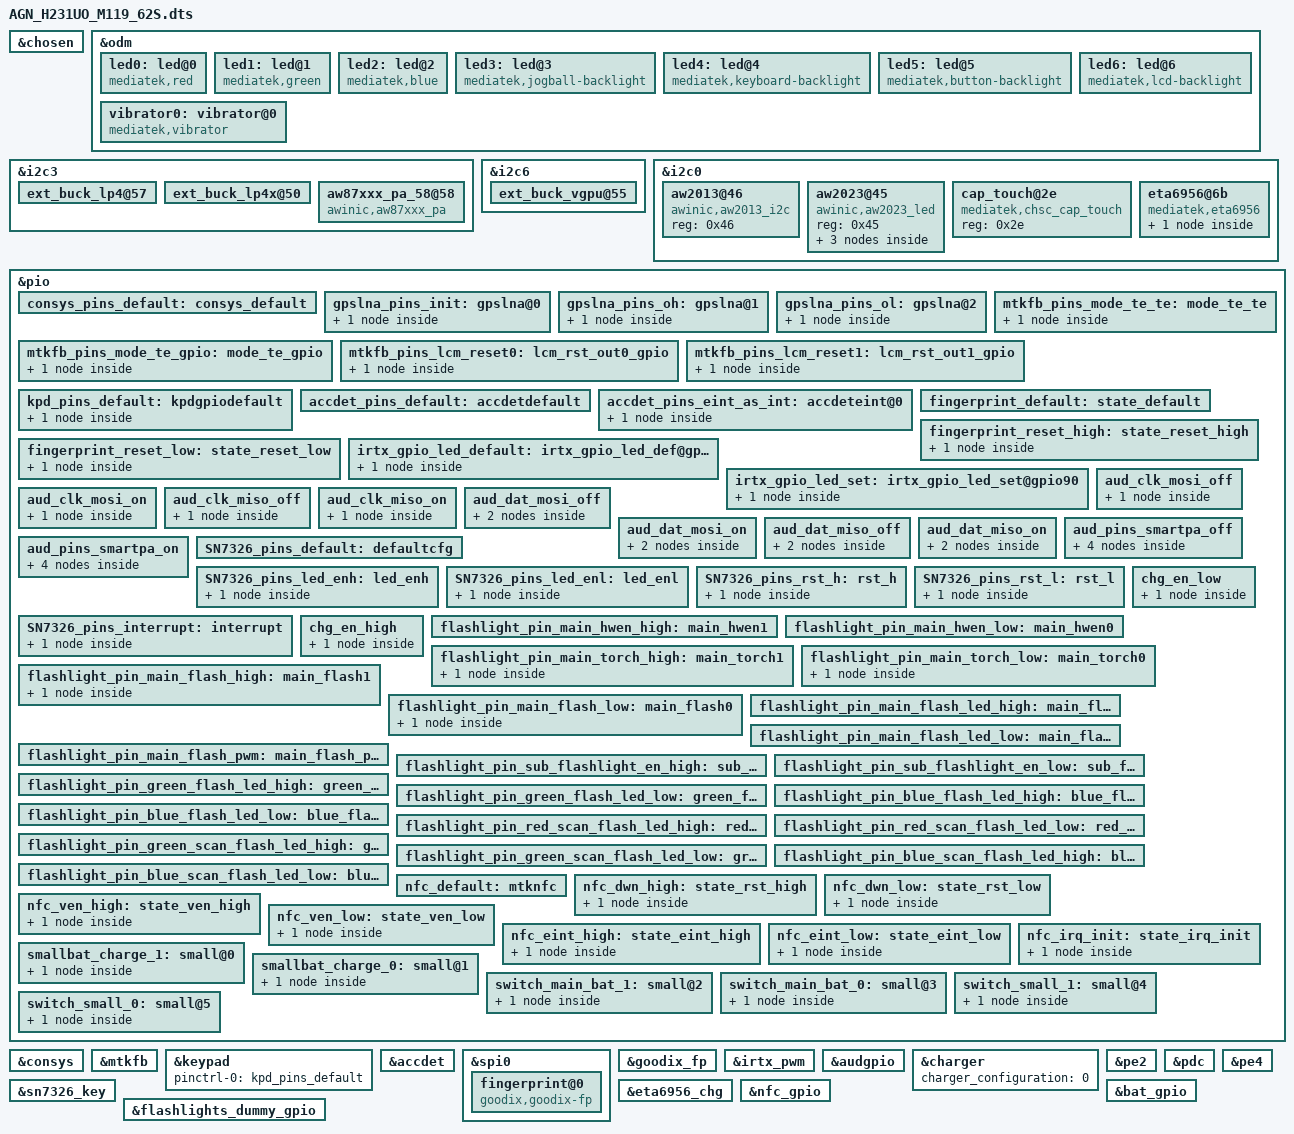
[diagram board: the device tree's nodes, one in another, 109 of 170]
// SPDX-License-Identifier: GPL-2.0+
/*
 * Copyright (c) 2019 MediaTek Inc.
 *
 */

#include <dt-bindings/interrupt-controller/arm-gic.h>
#include <dt-bindings/interrupt-controller/irq.h>
#include <dt-bindings/pinctrl/mt6765-pinfunc.h>
#include <dt-bindings/clock/mt6765-clk.h>

/dts-v1/;
/plugin/;

/* chosen */
&chosen {

	/* fpga may has no lk, we need to specify display info here */
	/* fb buffer is reserved using this dts by memory node above */
	atag,videolfb-fb_base_h = <0x0>;
	atag,videolfb-fb_base_l = <0x5e605000>;
	atag,videolfb-islcmfound = <1>;
	/* because no lk, so lcm is not inited */
	atag,videolfb-islcm_inited = <0>;
	atag,videolfb-fps= <6000>;
	atag,videolfb-vramSize= <0x017bb000>;
	atag,videolfb-lcmname= "nt35695B_fhd_dsi_cmd_auo_rt5081_drv";
};

&odm {
	led0:led@0 {
		compatible = "mediatek,red";
		led_mode = <0>;
		data = <2>;
		pwm_config = <0 0 0 0 0>;
	};
	led1:led@1 {
		compatible = "mediatek,green";
		led_mode = <0>;
		data = <1>;
		pwm_config = <0 0 0 0 0>;
	};
	led2:led@2 {
		compatible = "mediatek,blue";
		led_mode = <0>;
		data = <1>;
		pwm_config = <0 0 0 0 0>;
	};
	led3:led@3 {
		compatible = "mediatek,jogball-backlight";
		led_mode = <0>;
		data = <1>;
		pwm_config = <0 0 0 0 0>;
	};
	led4:led@4 {
		compatible = "mediatek,keyboard-backlight";
		led_mode = <0>;
		data = <1>;
		pwm_config = <0 0 0 0 0>;
	};
	led5:led@5 {
		compatible = "mediatek,button-backlight";
		led_mode = <2>;
		data = <1>;
		gpio = <&pio 165 0x0>;
		pwm_config = <0 0 0 0 0>;
	};
	led6:led@6 {
		compatible = "mediatek,lcd-backlight";
		led_mode = <5>;
		data = <1>;
		pwm_config = <0 3 0 0 0>;
	};
	vibrator0:vibrator@0 {
		compatible = "mediatek,vibrator";
		vib_timer = <25>;
		vib_limit = <9>;
		vib_vol= <9>;
	};
};

&i2c3 {
	ext_buck_lp4@57 {
		regulator-name ="ext_buck_vdd2";
		regulator-min-microvolt = <300000>;
		regulator-max-microvolt = <1300000>;
		vsel_pin = <0>;
	};

	ext_buck_lp4x@50 {
		regulator-name ="ext_buck_vddq";
		regulator-min-microvolt = <300000>;
		regulator-max-microvolt = <1300000>;
		vsel_pin = <1>;
	};
};

&i2c6 {
	ext_buck_vgpu@55 {
		regulator-name ="ext_buck_vgpu";
		regulator-min-microvolt = <300000>;
		regulator-max-microvolt = <1300000>;
		vsel_pin = <2>;
	};
};

&i2c0 {
	aw2013@46 {
		compatible = "awinic,aw2013_i2c";
		reg = <0x46>;
		status = "okay";
	};

	aw2023@45 {
	compatible = "awinic,aw2023_led";
	reg = <0x45>;
	status = "okay";
	
	aw2023,green  {
		aw2023,name = "green";
		aw2023,id = <0>;
		aw2023,imax = <1>;
		aw2023,led-current = <15>;
		aw2023,max-brightness = <255>;
		aw2023,rise-time-ms = <6>;
		aw2023,hold-time-ms = <0>;
		aw2023,fall-time-ms = <6>;
		aw2023,off-time-ms = <4>;
	};

	aw2023,scan_led {
		aw2023,name = "scan_led";
		aw2023,id = <1>;
		aw2023,imax = <1>;
		aw2023,led-current = <15>;
		aw2023,max-brightness = <255>;
		aw2023,rise-time-ms = <6>;
		aw2023,hold-time-ms = <0>;
		aw2023,fall-time-ms = <6>;
		aw2023,off-time-ms = <4>;
	};

	aw2023,blue {
		aw2023,name = "blue";
		aw2023,id = <2>;
		aw2023,imax = <1>;
		aw2023,led-current = <15>;
		aw2023,max-brightness = <255>;
		aw2023,rise-time-ms = <6>;
		aw2023,hold-time-ms = <0>;
		aw2023,fall-time-ms = <6>;
		aw2023,off-time-ms = <4>;
	};
	};
	};


&i2c3 {
/* AWINIC AW87XXX Smart K PA */
	aw87xxx_pa_58@58 {
		compatible = "awinic,aw87xxx_pa";
		reg = <0x58>;
		reset-gpio = <&pio 159 0>;
		pa-channel = < 0 >;
		status = "okay";
	};
/* AWINIC AW87XXX Smart K PA End */
};

/* CONSYS GPIO standardization */
&pio {
	consys_pins_default: consys_default {
	};
	gpslna_pins_init: gpslna@0 {
		pins_cmd_dat {
			pinmux = <PINMUX_GPIO153__FUNC_GPIO153>;
			slew-rate = <0>;
			bias-disable;
			output-low;
		};
	};
	gpslna_pins_oh: gpslna@1 {
		pins_cmd_dat {
			pinmux = <PINMUX_GPIO153__FUNC_GPIO153>;
			slew-rate = <1>;
			output-high;
		};
	};
	gpslna_pins_ol: gpslna@2 {
		pins_cmd_dat {
			pinmux = <PINMUX_GPIO153__FUNC_GPIO153>;
			slew-rate = <1>;
			output-low;
		};
	};
};
&consys {
	pinctrl-names = "default", "gps_lna_state_init",
		"gps_lna_state_oh", "gps_lna_state_ol";
	pinctrl-0 = <&consys_pins_default>;
	pinctrl-1 = <&gpslna_pins_init>;
	pinctrl-2 = <&gpslna_pins_oh>;
	pinctrl-3 = <&gpslna_pins_ol>;
	config_vcn28_pin = <1>;
	status = "okay";
};
/* CONSYS end */
/* DISPSYS GPIO standardization */
&pio {
	mtkfb_pins_mode_te_gpio: mode_te_gpio {
		pins_cmd_dat {
			pinmux = <PINMUX_GPIO44__FUNC_DSI_TE>;
		};
	};

	mtkfb_pins_mode_te_te: mode_te_te {
		pins_cmd_dat {
			pinmux = <PINMUX_GPIO44__FUNC_DSI_TE>;
		};
	};

	mtkfb_pins_lcm_reset0: lcm_rst_out0_gpio {
		pins_cmd_dat {
			pinmux = <PINMUX_GPIO45__FUNC_GPIO45>;
			slew-rate = <1>;
			output-low;
		};
	};

	mtkfb_pins_lcm_reset1: lcm_rst_out1_gpio {
		pins_cmd_dat {
			pinmux = <PINMUX_GPIO45__FUNC_GPIO45>;
			slew-rate = <1>;
			output-high;
		};
	};


};

&mtkfb {
	pinctrl-names = "mode_te_gpio", "mode_te_te", "lcm_rst_out0_gpio",
		"lcm_rst_out1_gpio";
	pinctrl-0 = <&mtkfb_pins_mode_te_gpio>;
	pinctrl-1 = <&mtkfb_pins_mode_te_te>;
	pinctrl-2 = <&mtkfb_pins_lcm_reset0>;
	pinctrl-3 = <&mtkfb_pins_lcm_reset1>;
	status = "okay";
};
/* DISPSYS GPIO standardization end */

&keypad {
	pinctrl-names = "default";
	pinctrl-0 = <&kpd_pins_default>;
};

&pio {
	kpd_pins_default: kpdgpiodefault {
		pins_cmd_dat {
			pinmux = <PINMUX_GPIO93__FUNC_KPCOL0>;
			bias-pull-up = <MTK_PUPD_SET_R1R0_10>;
			output-low;
			input-schmitt-enable;
		};
	};
};


/* accdet start */
&accdet {
	accdet-mic-vol = <6>;
	headset-mode-setting = <0x500 0x500 1 0x1f0 0x800 0x800 0x20 0x44>;
	accdet-plugout-debounce = <1>;
	accdet-mic-mode = <1>;
	headset-eint-level-pol = <8>;
	headset-three-key-threshold = <0 80 220 400>;
	headset-three-key-threshold-CDD = <0 121 192 600>;
	headset-four-key-threshold = <0 58 121 192 400>;
	pinctrl-names = "default", "state_eint_as_int";
	pinctrl-0 = <&accdet_pins_default>;
	pinctrl-1 = <&accdet_pins_eint_as_int>;
	status = "okay";
};
&pio {
	accdet_pins_default: accdetdefault {
	};
	accdet_pins_eint_as_int: accdeteint@0 {
		pins_cmd_dat {
			pinmux = <PINMUX_GPIO9__FUNC_GPIO9>;
			slew-rate = <0>;
			bias-disable;
		};
	};
};
/* accdet end */


&i2c0 {
	#address-cells = <1>;
	#size-cells = <0>;
	clock-frequency = <400000>;
	mediatek,use-open-drain;
	cap_touch@2e {
		compatible = "mediatek,chsc_cap_touch";
		reg = <0x2e>;
		status = "okay";
	};
};


/* FINGERPRINT start */
&spi0 {
	#address-cells = <1>;
	#size-cells = <0>;
	fingerprint@0 {
		compatible = "goodix,goodix-fp";
		reg = <0>;
		spi-max-frequency = <8000000>;
		netlink-event = <30>;
		status = "okay";
	};
};

&goodix_fp {
	pinctrl-names = "default", "reset_high", "reset_low";
	pinctrl-0 = <&fingerprint_default>;
	pinctrl-1 = <&fingerprint_reset_high>;
	pinctrl-2 = <&fingerprint_reset_low>;
	status = "okay";
};

&pio {
	fingerprint_default: state_default {
	};
	fingerprint_reset_high: state_reset_high {
		pins_cmd_dat {
			pinmux = <PINMUX_GPIO172__FUNC_GPIO172>;
			slew-rate = <1>;
			output-high;
		};
	};
	fingerprint_reset_low: state_reset_low {
		pins_cmd_dat {
			pinmux = <PINMUX_GPIO172__FUNC_GPIO172>;
			slew-rate = <1>;
			output-low;
		};
	};
};
/* FINGERPRINT end */

/* IRTX GPIO end */
&irtx_pwm {
	pinctrl-names = "irtx_gpio_led_default", "irtx_gpio_led_set";
	pinctrl-0 = <&irtx_gpio_led_default>;
	pinctrl-1 = <&irtx_gpio_led_set>;
	status = "okay";
};
&pio {
	irtx_gpio_led_default:irtx_gpio_led_def@gpio90 {
		pins_cmd_dat {
			pinmux = <PINMUX_GPIO90__FUNC_GPIO90>;
			slew-rate = <1>;
			bias-disable;
			output-low;
			input-schmitt-enable = <0>;
		};
	};

	irtx_gpio_led_set:irtx_gpio_led_set@gpio90 {
		pins_cmd_dat {
			pinmux = <PINMUX_GPIO90__FUNC_PWM0>;
			slew-rate = <1>;
			output-high;
		};
	};
};
/* IRTX GPIO Settings -End */

/* AUDIO GPIO standardization */
&audgpio {
	pinctrl-names = "aud_clk_mosi_off",
			"aud_clk_mosi_on",
			"aud_clk_miso_off",
			"aud_clk_miso_on",
			"aud_dat_mosi_off",
			"aud_dat_mosi_on",
			"aud_dat_miso_off",
			"aud_dat_miso_on",
			"aud_smartpa_off",
			"aud_smartpa_on";
	pinctrl-0 = <&aud_clk_mosi_off>;
	pinctrl-1 = <&aud_clk_mosi_on>;
	pinctrl-2 = <&aud_clk_miso_off>;
	pinctrl-3 = <&aud_clk_miso_on>;
	pinctrl-4 = <&aud_dat_mosi_off>;
	pinctrl-5 = <&aud_dat_mosi_on>;
	pinctrl-6 = <&aud_dat_miso_off>;
	pinctrl-7 = <&aud_dat_miso_on>;
	pinctrl-8 = <&aud_pins_smartpa_off>;
	pinctrl-9 = <&aud_pins_smartpa_on>;
	status = "okay";
};

&pio {
	aud_clk_mosi_off: aud_clk_mosi_off {
		pins_cmd0_dat {
			pinmux = <PINMUX_GPIO136__FUNC_GPIO136>;
		};
	};

	aud_clk_mosi_on: aud_clk_mosi_on {
		pins_cmd0_dat {
			pinmux = <PINMUX_GPIO136__FUNC_AUD_CLK_MOSI>;
		};
	};

	aud_clk_miso_off: aud_clk_miso_off {
		pins_cmd0_dat {
			pinmux = <PINMUX_GPIO140__FUNC_GPIO140>;
		};
	};

	aud_clk_miso_on: aud_clk_miso_on {
		pins_cmd0_dat {
			pinmux = <PINMUX_GPIO140__FUNC_AUD_CLK_MISO>;
		};
	};

	aud_dat_mosi_off: aud_dat_mosi_off {
		pins_cmd1_dat {
			pinmux = <PINMUX_GPIO138__FUNC_GPIO138>;
			input-enable;
			slew-rate = <0>;
			bias-disable;
		};
		pins_cmd2_dat {
			pinmux = <PINMUX_GPIO139__FUNC_GPIO139>;
			input-enable;
			slew-rate = <0>;
			bias-disable;
		};
	};

	aud_dat_mosi_on: aud_dat_mosi_on {
		pins_cmd1_dat {
			pinmux = <PINMUX_GPIO138__FUNC_AUD_DAT_MOSI0>;
		};
		pins_cmd2_dat {
			pinmux = <PINMUX_GPIO139__FUNC_AUD_DAT_MOSI1>;
		};
	};

	aud_dat_miso_off: aud_dat_miso_off {
		pins_cmd1_dat {
			pinmux = <PINMUX_GPIO142__FUNC_GPIO142>;
			input-enable;
			slew-rate = <0>;
			bias-disable;
		};
		pins_cmd2_dat {
			pinmux = <PINMUX_GPIO143__FUNC_GPIO143>;
			input-enable;
			slew-rate = <0>;
			bias-disable;
		};
	};

	aud_dat_miso_on: aud_dat_miso_on {
		pins_cmd1_dat {
			pinmux = <PINMUX_GPIO142__FUNC_AUD_DAT_MISO0>;
		};
		pins_cmd2_dat {
			pinmux = <PINMUX_GPIO143__FUNC_AUD_DAT_MISO1>;
		};
	};

	aud_pins_smartpa_off: aud_pins_smartpa_off {
		pins_cmd0_dat {
			pinmux = <PINMUX_GPIO17__FUNC_GPIO17>;
		};
		pins_cmd1_dat {
			pinmux = <PINMUX_GPIO18__FUNC_GPIO18>;
		};
		pins_cmd2_dat {
			pinmux = <PINMUX_GPIO19__FUNC_GPIO19>;
		};
		pins_cmd3_dat {
			pinmux = <PINMUX_GPIO20__FUNC_GPIO20>;
		};
	};

	aud_pins_smartpa_on: aud_pins_smartpa_on {
		pins_cmd0_dat {
			pinmux = <PINMUX_GPIO17__FUNC_I2S0_DI>;
		};
		pins_cmd1_dat {
			pinmux = <PINMUX_GPIO18__FUNC_I2S3_BCK>;
		};
		pins_cmd2_dat {
			pinmux = <PINMUX_GPIO19__FUNC_I2S3_LRCK>;
		};
		pins_cmd3_dat {
			pinmux = <PINMUX_GPIO20__FUNC_I2S3_DO>;
		};
	};
};
/* AUDIO end */



&i2c3 {

};

&charger {
	charger_configuration= <0>;
};

&pe2 {
	dcs_chg1_charger_current = <2000000>;
	dcs_chg2_charger_current = <2000000>;
};

&pdc {
	pd_vbus_upper_bound = <12000000>;
	dcs_chg1_charger_current = <2000000>;
	dcs_chg2_charger_current = <2000000>;
};

&pe4 {
	dcs_chg1_charger_current = <2000000>;
	dcs_chg2_charger_current = <2000000>;
};
/*SN7326, start */

&pio {
	SN7326_pins_default:defaultcfg {
	};
	SN7326_pins_led_enh:led_enh {
			pins_cmd_dat {
			pinmux = <PINMUX_GPIO165__FUNC_GPIO165>;
			slew-rate = <1>;
			output-high;
		};
	};
	SN7326_pins_led_enl:led_enl {
			pins_cmd_dat {
			pinmux = <PINMUX_GPIO165__FUNC_GPIO165>;
			slew-rate = <1>;
			output-low;
		};
	};
	SN7326_pins_rst_h:rst_h {
			pins_cmd_dat {
			pinmux = <PINMUX_GPIO171__FUNC_GPIO171>;
			slew-rate = <1>;
			output-high;
		};
	};
	SN7326_pins_rst_l:rst_l {
			pins_cmd_dat {
			pinmux = <PINMUX_GPIO171__FUNC_GPIO171>;
			slew-rate = <1>;
			output-low;
		};
	};
	SN7326_pins_interrupt:interrupt {
			pins_cmd_dat {
			pinmux = <PINMUX_GPIO12__FUNC_GPIO12>;
			slew-rate = <0>;
			bias-pull-up = <00>;
		};
	};
};

&sn7326_key {
	pinctrl-names = "default", "led_enh", "led_enl", "rst_h", "rst_l", "interrupt";
	pinctrl-0 = <&SN7326_pins_default>;
	pinctrl-1 = <&SN7326_pins_led_enh>;
	pinctrl-2 = <&SN7326_pins_led_enl>;
	pinctrl-3 = <&SN7326_pins_rst_h>;
	pinctrl-4 = <&SN7326_pins_rst_l>;
	pinctrl-5 = <&SN7326_pins_interrupt>;
	status = "okay";
};

/*SN7326, end */
&i2c0 {
		eta6956@6b {
				status = "okay";
				compatible = "mediatek,eta6956";
				reg = <0x6b>;    //   0x6B(7-bit)   0xD6(8-bit)

				/*
				* Charger name
				* Main charger: primary_chg
				* Slave charger: secondary_chg
				*/
				charger_name = "primary_chg";
				alias_name = "eta6956";
		ichg = <1500000>; /* uA */
		aicr = <500000>;  /* uA */
		mivr = <4500000>; /* uV */
		ieoc = <200000>;  /* uA */
		cv = <4400000>; /* uV */
		vmreg = <4360000>; /* uV */
		enable_te;
		enable_eoc_shdn;
		otg_vbus: usb-otg-vbus {
				regulator-compatible = "usb-otg-vbus";
				regulator-name = "usb-otg-vbus";
				regulator-min-microvolt = <4350000>;
				regulator-max-microvolt = <5800000>;
				regulator-min-microamp = <500000>;
				regulator-max-microamp = <3000000>;
		};
	};
	
	

};
	


&eta6956_chg {      
    pinctrl-names = "psc_chg_en_low", "psc_chg_en_high";
    pinctrl-0 = <&chg_en_low>;
	pinctrl-1 = <&chg_en_high>;
};
	
&pio {
	chg_en_low: chg_en_low {
		pins_cmd_dat {
			pinmux = <PINMUX_GPIO154__FUNC_GPIO154>;
			slew-rate = <1>;
			bias-disable;
			output-low;
		};
	};
	
	chg_en_high: chg_en_high {
		pins_cmd_dat {
			pinmux = <PINMUX_GPIO154__FUNC_GPIO154>;
			slew-rate = <1>;
			bias-disable;
			output-high;
		};
	};
};


/*flashlight, begin by maliejun, @2017-11-03 16:06:06*/
&pio {
	flashlight_pin_main_hwen_high: main_hwen1 {
	};
	flashlight_pin_main_hwen_low: main_hwen0 {
	};
	flashlight_pin_main_torch_high: main_torch1 {
		pins_cmd_dat {
			pinmux = <PINMUX_GPIO90__FUNC_GPIO90>;
			slew-rate = <1>;
			output-high;
		};
	};
	flashlight_pin_main_torch_low: main_torch0 {
		pins_cmd_dat {
			pinmux = <PINMUX_GPIO90__FUNC_GPIO90>;
			slew-rate = <1>;
			output-low;
		};
	};
	flashlight_pin_main_flash_high: main_flash1 {
		pins_cmd_dat {
			pinmux = <PINMUX_GPIO89__FUNC_GPIO89>;
			slew-rate = <1>;
			output-high;
		};
	};
	flashlight_pin_main_flash_low: main_flash0 {
		pins_cmd_dat {
			pinmux = <PINMUX_GPIO89__FUNC_GPIO89>;
			slew-rate = <1>;
			output-low;
		};
	};
	flashlight_pin_main_flash_led_high: main_flash_led1 {
	};
	flashlight_pin_main_flash_led_low: main_flash_led0 {
	};
	flashlight_pin_main_flash_pwm: main_flash_pwm {
	};
	flashlight_pin_sub_flashlight_en_high: sub_flashlight_en1 {
	};
	flashlight_pin_sub_flashlight_en_low: sub_flashlight_en0 {
	};
	
	flashlight_pin_green_flash_led_high: green_flash_led1 {
	};
	flashlight_pin_green_flash_led_low: green_flash_led0 {
	};
	
	flashlight_pin_blue_flash_led_high: blue_flash_led1 {

	};
	flashlight_pin_blue_flash_led_low: blue_flash_led0 {

	};
		
	flashlight_pin_red_scan_flash_led_high: red_scan_flash_led1 {
	};
	flashlight_pin_red_scan_flash_led_low: red_scan_flash_led0 {
	};
		
	flashlight_pin_green_scan_flash_led_high: green_scan_flash_led1 {
	};
	flashlight_pin_green_scan_flash_led_low: green_scan_flash_led0 {
	};
		
	flashlight_pin_blue_scan_flash_led_high: blue_scan_flash_led1 {
	};
	flashlight_pin_blue_scan_flash_led_low: blue_scan_flash_led0 {
	};
};
&flashlights_dummy_gpio{
	pinctrl-names = "hwen_high", "hwen_low", "torch_high", "torch_low", "flash_high", "flash_low", "flash_led_high", "flash_led_low","flash_pwm","sub_flashlight_en_high","sub_flashlight_en_low","green_led_high", "green_led_low","blue_led_high", "blue_led_low","red_scan_led_high", "red_scan_led_low","green_scan_led_high", "green_scan_led_low","blue_scan_led_high", "blue_scan_led_low";
	pinctrl-0 = <&flashlight_pin_main_hwen_high>;
	pinctrl-1 = <&flashlight_pin_main_hwen_low>;
	pinctrl-2 = <&flashlight_pin_main_torch_high>;
	pinctrl-3 = <&flashlight_pin_main_torch_low>;
	pinctrl-4 = <&flashlight_pin_main_flash_high>;
	pinctrl-5 = <&flashlight_pin_main_flash_low>;
	pinctrl-6 = <&flashlight_pin_main_flash_led_high>;
	pinctrl-7 = <&flashlight_pin_main_flash_led_low>;
	pinctrl-8 = <&flashlight_pin_main_flash_pwm>;
	pinctrl-9 = <&flashlight_pin_sub_flashlight_en_high>;
	pinctrl-10 = <&flashlight_pin_sub_flashlight_en_low>;
	pinctrl-11 = <&flashlight_pin_green_flash_led_high>;
	pinctrl-12 = <&flashlight_pin_green_flash_led_low>;
	pinctrl-13 = <&flashlight_pin_blue_flash_led_high>;
	pinctrl-14 = <&flashlight_pin_blue_flash_led_low>;
	pinctrl-15 = <&flashlight_pin_red_scan_flash_led_high>;
	pinctrl-16 = <&flashlight_pin_red_scan_flash_led_low>;
	pinctrl-17 = <&flashlight_pin_green_scan_flash_led_high>;
	pinctrl-18 = <&flashlight_pin_green_scan_flash_led_low>;
	pinctrl-19 = <&flashlight_pin_blue_scan_flash_led_high>;
	pinctrl-20 = <&flashlight_pin_blue_scan_flash_led_low>;
	status = "okay";
};
/*flashlight, end by maliejun, @2017-11-03 16:06:10*/

&nfc_gpio {      
    interrupt-parent = <&pio>;
    pinctrl-names = "mtknfc", "ven_high", "ven_low", "dwn_high", "dwn_low", "eint_high", "eint_low", "irq_init";
    pinctrl-0 = <&nfc_default>;
    pinctrl-1 = <&nfc_ven_high>;
    pinctrl-2 = <&nfc_ven_low>;
    pinctrl-3 = <&nfc_dwn_high>;
    pinctrl-4 = <&nfc_dwn_low>;
    pinctrl-5 = <&nfc_eint_high>;
    pinctrl-6 = <&nfc_eint_low>;
    pinctrl-7 = <&nfc_irq_init>;
};

/* NFC GPIO standardization */
&pio {
	nfc_default: mtknfc {

	};
	nfc_dwn_high: state_rst_high {
		pins_cmd_dat {
			pinmux = <PINMUX_GPIO167__FUNC_GPIO167>;
			slew-rate = <1>;
			output-high;
		};
	};
	nfc_dwn_low: state_rst_low {
		pins_cmd_dat {
			pinmux = <PINMUX_GPIO167__FUNC_GPIO167>;
			slew-rate = <1>;
			output-low;
		};
	};
	nfc_ven_high: state_ven_high {
		pins_cmd_dat {
			pinmux = <PINMUX_GPIO166__FUNC_GPIO166>;
			slew-rate = <1>;
			output-high;
		};
	};
	nfc_ven_low: state_ven_low {
		pins_cmd_dat {
			pinmux = <PINMUX_GPIO166__FUNC_GPIO166>;
			slew-rate = <1>;
			output-low;
		};
	};
	nfc_eint_high: state_eint_high {
		pins_cmd_dat {
			pinmux = <PINMUX_GPIO5__FUNC_GPIO5>;
			slew-rate = <1>;
			output-high;
		};
	};
	nfc_eint_low: state_eint_low {
		pins_cmd_dat {
			pinmux = <PINMUX_GPIO5__FUNC_GPIO5>;
			slew-rate = <1>;
			output-low;
		};
	};
	nfc_irq_init: state_irq_init {
		pins_cmd_dat {
			pinmux = <PINMUX_GPIO5__FUNC_GPIO5>;
			slew-rate = <0>;
			bias-pull-down = <00>;
		};
	};
};
/* NFC end */


&bat_gpio {
	pinctrl-names = "smallbat_charge_hight","smallbat_charge_low","switch_main_bat_hight","switch_main_bat_low","switch_small_bat_hight","switch_small_bat_low";
	pinctrl-0 = <&smallbat_charge_1>;
	pinctrl-1= <&smallbat_charge_0>;
	pinctrl-2= <&switch_main_bat_1>;
	pinctrl-3= <&switch_main_bat_0>;
	pinctrl-4 = <&switch_small_1>;
	pinctrl-5= <&switch_small_0>;
	status = "okay";
};
	
&pio {
	smallbat_charge_1:small@0{
		pins_cmd1_dat {
			pinmux = <PINMUX_GPIO78__FUNC_GPIO78>;
			slew-rate = <1>;
			bias-disable;
			output-high;
		};
	};
		
	smallbat_charge_0:small@1{
		pins_cmd1_dat {
			pinmux = <PINMUX_GPIO78__FUNC_GPIO78>;
			slew-rate = <1>;
			bias-disable;
			output-low;
		};
	};

	switch_main_bat_1:small@2{
		pins_cmd1_dat {
			pinmux = <PINMUX_GPIO172__FUNC_GPIO172>;
			slew-rate = <1>;
			bias-disable;
			output-high;
		};
	};
		
	switch_main_bat_0:small@3{
		pins_cmd1_dat {
			pinmux = <PINMUX_GPIO172__FUNC_GPIO172>;
			slew-rate = <1>;
			bias-disable;
			output-low;
		};
	};
	switch_small_1:small@4{
		pins_cmd1_dat {
			pinmux = <PINMUX_GPIO57__FUNC_GPIO57>;
			slew-rate = <1>;
			bias-disable;
			output-high;
		};
	};
		
	switch_small_0:small@5{
		pins_cmd1_dat {
			pinmux = <PINMUX_GPIO57__FUNC_GPIO57>;
			slew-rate = <1>;
			bias-disable;
			output-low;
		};
	};
};

#include "AGN_H231UO_M119_62S/cust.dtsi"
#include "mediatek/AGN_H231UO_M119_62S/cust_mt6765_camera.dtsi"
#include "mediatek/AGN_H231UO_M119_62S/cust_mt6765_touch_480x800.dtsi"
/*End of this file, DO NOT ADD ANYTHING HERE*/
